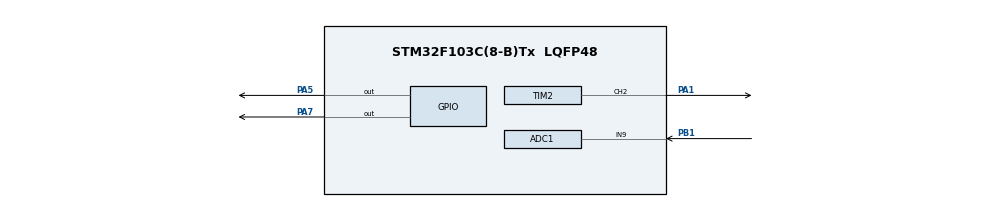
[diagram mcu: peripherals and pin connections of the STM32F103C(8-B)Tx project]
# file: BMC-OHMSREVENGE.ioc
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ADC1.Channel-0\#ChannelRegularConversion=ADC_CHANNEL_9
ADC1.ContinuousConvMode=ENABLE
ADC1.NbrOfConversionFlag=1
ADC1.Rank-0\#ChannelRegularConversion=1
ADC1.SamplingTime-0\#ChannelRegularConversion=ADC_SAMPLETIME_1CYCLE_5
ADC1.master=1
Mcu.Family=STM32F1
Mcu.Name=STM32F103C(8-B)Tx
Mcu.Package=LQFP48
NVIC.PriorityGroup=NVIC_PRIORITYGROUP_4
PA1.Signal=S_TIM2_CH2
PA13.Mode=Serial_Wire
PA13.Signal=SYS_JTMS-SWDIO
PA14.Mode=Serial_Wire
PA14.Signal=SYS_JTCK-SWCLK
PA5.Signal=GPIO_Output
PA7.Signal=GPIO_Output
PB1.Signal=ADCx_IN9
ProjectManager.HeapSize=0x200
ProjectManager.StackSize=0x400
ProjectManager.TargetToolchain=STM32CubeIDE
RCC.APB1Freq_Value=8000000
RCC.APB2Freq_Value=8000000
SH.ADCx_IN9.0=ADC1_IN9,IN9
SH.S_TIM2_CH2.0=TIM2_CH2,PWM Generation2 CH2
TIM2.Channel-PWM\ Generation2\ CH2=TIM_CHANNEL_2
TIM2.Period=625
TIM2.Prescaler=127
VP_TIM2_VS_ClockSourceINT.Mode=Internal
board=custom

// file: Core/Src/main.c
/* USER CODE BEGIN Header */
/**
  ******************************************************************************
  * @file           : main.c
  * @brief          : Main program body
  ******************************************************************************
  * @attention
  *
  * Copyright (c) 2025 STMicroelectronics.
  * All rights reserved.
  *
  * This software is licensed under terms that can be found in the LICENSE file
  * in the root directory of this software component.
  * If no LICENSE file comes with this software, it is provided AS-IS.
  *
  ******************************************************************************
  */
/* USER CODE END Header */
#include "main.h"

ADC_HandleTypeDef hadc1;

TIM_HandleTypeDef htim2;

void SystemClock_Config(void);
static void MX_GPIO_Init(void);
static void MX_ADC1_Init(void);
static void MX_TIM2_Init(void);

int main(void)
{

  /* MCU Configuration--------------------------------------------------------*/

  /* Reset of all peripherals, Initializes the Flash interface and the Systick. */
	HAL_Init();

	/* Configure the system clock */
	SystemClock_Config();

	/* Initialize all configured peripherals */
	MX_GPIO_Init();
	MX_ADC1_Init();
	MX_TIM2_Init();
  /* USER CODE BEGIN 2 */
	HAL_ADC_Start(&hadc1);  //PB1
	HAL_TIM_PWM_Start(&htim2, TIM_CHANNEL_2); //PA1 TIM2 CH2
	uint16_t readValue;
	int speed;
	HAL_GPIO_WritePin(GPIOA, GPIO_PIN_7, 0);
	HAL_GPIO_WritePin(GPIOA, GPIO_PIN_5, 0);
    /* USER CODE END 2 */

    /* Infinite loop */
    /* USER CODE BEGIN WHILE */
    while (1)
    {
      HAL_ADC_PollForConversion(&hadc1,1000);
      readValue = HAL_ADC_GetValue(&hadc1);
      if (readValue < 1790) {
        HAL_GPIO_WritePin(GPIOA, GPIO_PIN_7, 0);
        HAL_GPIO_WritePin(GPIOA, GPIO_PIN_5, 1);
        speed = (readValue - 1790) * (-1) / 3;
      } else if (readValue > 2220) {
        HAL_GPIO_WritePin(GPIOA, GPIO_PIN_5, 0);
        HAL_GPIO_WritePin(GPIOA, GPIO_PIN_7, 1);
        speed = (readValue - 2220) / 3;
      } else {
        speed = 0;
      }
      __HAL_TIM_SET_COMPARE(&htim2,TIM_CHANNEL_2, speed);
      HAL_Delay(50);
    }
  /* USER CODE END 2 */
  /* USER CODE END 3 */
}

void SystemClock_Config(void)
{
  RCC_OscInitTypeDef RCC_OscInitStruct = {0};
  RCC_ClkInitTypeDef RCC_ClkInitStruct = {0};
  RCC_PeriphCLKInitTypeDef PeriphClkInit = {0};

  /** Initializes the RCC Oscillators according to the specified parameters
  * in the RCC_OscInitTypeDef structure.
  */
  RCC_OscInitStruct.OscillatorType = RCC_OSCILLATORTYPE_HSI;
  RCC_OscInitStruct.HSIState = RCC_HSI_ON;
  RCC_OscInitStruct.HSICalibrationValue = RCC_HSICALIBRATION_DEFAULT;
  RCC_OscInitStruct.PLL.PLLState = RCC_PLL_NONE;
  if (HAL_RCC_OscConfig(&RCC_OscInitStruct) != HAL_OK)
  {
    Error_Handler();
  }

  /** Initializes the CPU, AHB and APB buses clocks
  */
  RCC_ClkInitStruct.ClockType = RCC_CLOCKTYPE_HCLK|RCC_CLOCKTYPE_SYSCLK
                              |RCC_CLOCKTYPE_PCLK1|RCC_CLOCKTYPE_PCLK2;
  RCC_ClkInitStruct.SYSCLKSource = RCC_SYSCLKSOURCE_HSI;
  RCC_ClkInitStruct.AHBCLKDivider = RCC_SYSCLK_DIV1;
  RCC_ClkInitStruct.APB1CLKDivider = RCC_HCLK_DIV1;
  RCC_ClkInitStruct.APB2CLKDivider = RCC_HCLK_DIV1;

  if (HAL_RCC_ClockConfig(&RCC_ClkInitStruct, FLASH_LATENCY_0) != HAL_OK)
  {
    Error_Handler();
  }
  PeriphClkInit.PeriphClockSelection = RCC_PERIPHCLK_ADC;
  PeriphClkInit.AdcClockSelection = RCC_ADCPCLK2_DIV2;
  if (HAL_RCCEx_PeriphCLKConfig(&PeriphClkInit) != HAL_OK)
  {
    Error_Handler();
  }
}

static void MX_ADC1_Init(void)
{

  ADC_ChannelConfTypeDef sConfig = {0};

  /** Common config
  */
  hadc1.Instance = ADC1;
  hadc1.Init.ScanConvMode = ADC_SCAN_DISABLE;
  hadc1.Init.ContinuousConvMode = ENABLE;
  hadc1.Init.DiscontinuousConvMode = DISABLE;
  hadc1.Init.ExternalTrigConv = ADC_SOFTWARE_START;
  hadc1.Init.DataAlign = ADC_DATAALIGN_RIGHT;
  hadc1.Init.NbrOfConversion = 1;
  if (HAL_ADC_Init(&hadc1) != HAL_OK)
  {
    Error_Handler();
  }

  /** Configure Regular Channel
  */
  sConfig.Channel = ADC_CHANNEL_9;
  sConfig.Rank = ADC_REGULAR_RANK_1;
  sConfig.SamplingTime = ADC_SAMPLETIME_1CYCLE_5;
  if (HAL_ADC_ConfigChannel(&hadc1, &sConfig) != HAL_OK)
  {
    Error_Handler();
  }

}

static void MX_TIM2_Init(void)
{

  TIM_ClockConfigTypeDef sClockSourceConfig = {0};
  TIM_MasterConfigTypeDef sMasterConfig = {0};
  TIM_OC_InitTypeDef sConfigOC = {0};

  htim2.Instance = TIM2;
  htim2.Init.Prescaler = 127;
  htim2.Init.CounterMode = TIM_COUNTERMODE_UP;
  htim2.Init.Period = 625;
  htim2.Init.ClockDivision = TIM_CLOCKDIVISION_DIV1;
  htim2.Init.AutoReloadPreload = TIM_AUTORELOAD_PRELOAD_DISABLE;
  if (HAL_TIM_Base_Init(&htim2) != HAL_OK)
  {
    Error_Handler();
  }
  sClockSourceConfig.ClockSource = TIM_CLOCKSOURCE_INTERNAL;
  if (HAL_TIM_ConfigClockSource(&htim2, &sClockSourceConfig) != HAL_OK)
  {
    Error_Handler();
  }
  if (HAL_TIM_PWM_Init(&htim2) != HAL_OK)
  {
    Error_Handler();
  }
  sMasterConfig.MasterOutputTrigger = TIM_TRGO_RESET;
  sMasterConfig.MasterSlaveMode = TIM_MASTERSLAVEMODE_DISABLE;
  if (HAL_TIMEx_MasterConfigSynchronization(&htim2, &sMasterConfig) != HAL_OK)
  {
    Error_Handler();
  }
  sConfigOC.OCMode = TIM_OCMODE_PWM1;
  sConfigOC.Pulse = 0;
  sConfigOC.OCPolarity = TIM_OCPOLARITY_HIGH;
  sConfigOC.OCFastMode = TIM_OCFAST_DISABLE;
  if (HAL_TIM_PWM_ConfigChannel(&htim2, &sConfigOC, TIM_CHANNEL_2) != HAL_OK)
  {
    Error_Handler();
  }
  HAL_TIM_MspPostInit(&htim2);

}

static void MX_GPIO_Init(void)
{
  GPIO_InitTypeDef GPIO_InitStruct = {0};

  /* GPIO Ports Clock Enable */
  __HAL_RCC_GPIOA_CLK_ENABLE();
  __HAL_RCC_GPIOB_CLK_ENABLE();

  /*Configure GPIO pin Output Level */
  HAL_GPIO_WritePin(GPIOA, GPIO_PIN_5|GPIO_PIN_7, GPIO_PIN_RESET);

  /*Configure GPIO pins : PA5 PA7 */
  GPIO_InitStruct.Pin = GPIO_PIN_5|GPIO_PIN_7;
  GPIO_InitStruct.Mode = GPIO_MODE_OUTPUT_PP;
  GPIO_InitStruct.Pull = GPIO_NOPULL;
  GPIO_InitStruct.Speed = GPIO_SPEED_FREQ_LOW;
  HAL_GPIO_Init(GPIOA, &GPIO_InitStruct);

}

void Error_Handler(void)
{
  __disable_irq();
  while (1)
  {
  }
}
